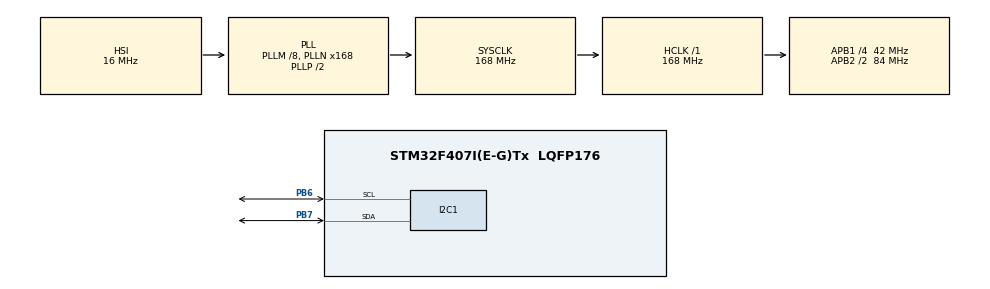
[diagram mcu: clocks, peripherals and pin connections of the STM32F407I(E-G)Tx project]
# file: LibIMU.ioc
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Mcu.Family=STM32F4
Mcu.Name=STM32F407I(E-G)Tx
Mcu.Package=LQFP176
NVIC.PriorityGroup=NVIC_PRIORITYGROUP_4
NVIC.TIM7_IRQn=true\:0\:0\:false\:false\:true\:true\:true\:true
PB6.Mode=I2C
PB6.Signal=I2C1_SCL
PB7.Mode=I2C
PB7.Signal=I2C1_SDA
ProjectManager.HeapSize=0x200
ProjectManager.StackSize=0x400
ProjectManager.TargetToolchain=STM32CubeIDE
RCC.48MHZClocksFreq_Value=84000000
RCC.AHBFreq_Value=168000000
RCC.APB1CLKDivider=RCC_HCLK_DIV4
RCC.APB1Freq_Value=42000000
RCC.APB1TimFreq_Value=84000000
RCC.APB2CLKDivider=RCC_HCLK_DIV2
RCC.APB2Freq_Value=84000000
RCC.APB2TimFreq_Value=168000000
RCC.CortexFreq_Value=168000000
RCC.HCLKFreq_Value=168000000
RCC.HSE_VALUE=25000000
RCC.HSI_VALUE=16000000
RCC.LSE_VALUE=32768
RCC.PLLM=8
RCC.PLLN=168
RCC.SYSCLKFreq_VALUE=168000000
RCC.SYSCLKSource=RCC_SYSCLKSOURCE_PLLCLK
RCC.VCOOutputFreq_Value=336000000
TIM7.Period=21000-1
TIM7.Prescaler=100-1
VP_TIM7_VS_ClockSourceINT.Mode=Enable_Timer
board=custom

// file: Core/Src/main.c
/* USER CODE BEGIN Header */
/**
  ******************************************************************************
  * @file           : main.c
  * @brief          : Main program body
  ******************************************************************************
  * @attention
  *
  * Copyright (c) 2022 STMicroelectronics.
  * All rights reserved.
  *
  * This software is licensed under terms that can be found in the LICENSE file
  * in the root directory of this software component.
  * If no LICENSE file comes with this software, it is provided AS-IS.
  *
  ******************************************************************************
  */
/* USER CODE END Header */
#include "main.h"

/* USER CODE BEGIN Includes */

#include "Inc/IMU.h"

/* USER CODE END Includes */

// I2C_HandleTypeDef hi2c1;

TIM_HandleTypeDef htim7;

/* USER CODE BEGIN PV */

 int Test=0;
/* USER CODE END PV */

void SystemClock_Config(void);
static void MX_GPIO_Init(void);
static void MX_I2C1_Init(void);
static void MX_TIM7_Init(void);

/* USER CODE BEGIN 0 */
 void HAL_TIM_PeriodElapsedCallback (TIM_HandleTypeDef *htim)
 {
 	if(htim==&htim7)
 	{

	UpdateRpy();

//
//
// 				/********** ACCEL data ***********/
// 		        // get the accelerometer data relative to the 3 axis :
// 				AccEst[0] =GetAccX() ;
// 				AccEst[1] = GetAccY() ;
// 				AccEst[2] = GetAccZ() ;
//
// 		        /********** MAG data ***********/
// 		         // get the magnetometer data relative to the 3 axis :
// 		        MagEst[0] = GetMagX() ;
// 		        MagEst[1] = GetMagY() ;
// 		        MagEst[2] = GetMagZ() ;
//
// 		        //KALMAN FILTERS:
// 		        //  application of the Kalman filter on the data of the three sensors
// 		        KalmanFilterACC(AccEst) ;
// 		        //  KalmanFilterGYRO(GYRO_est) ;
// 		        KalmanFilterMAG(MagEst) ;
//
//
// 		        // Normalize the data :
// 		         NormMag = sqrtf ((MagEst[0]*MagEst[0])+(MagEst[1]*MagEst[1])+(MagEst[2]*MagEst[2])) ;
// 		         MagEst[0] = MagEst[0]/NormMag ;
// 		         MagEst[1] = MagEst[1]/NormMag ;
// 		         MagEst[2] = MagEst[2]/NormMag ;
//
// 		         NormAcc = sqrt((AccEst[0]*AccEst[0])+(AccEst[1]*AccEst[1])+(AccEst[2]*AccEst[2])) ;
// 		         AccEst[0] = AccEst[0]/NormAcc ;
// 		         AccEst[1] = AccEst[1]/NormAcc ;
// 		         AccEst[2] = AccEst[2]/NormAcc ;
//
//
//
//
//
// 		        //Calculation of the three angles:
// 		          RollDeg =  180*atan2f(AccEst[1],AccEst[2])/M_PI;
// 		          PitchDeg = 180*atan2f(AccEst[0],AccEst[2])/M_PI;
// 		          Roll =  atan2f(AccEst[1],AccEst[2]);
// 		          Pitch = atan2f(AccEst[0],AccEst[2]);
// 		          Yaw=180*atan2f((-MagEst[1]*cosf(Roll)+MagEst[2]*sinf(Roll)),(MagEst[0]*cosf(Pitch)+MagEst[1]*sinf(Pitch)*sinf(Roll)+MagEst[2]*sinf(Pitch)*cos(Roll)))/M_PI+180;
// 		          if (Yaw>0) Yaw = Yaw-360 ;
// 		          Yaw=-Yaw;

 	}

 }
/* USER CODE END 0 */

int main(void)
{

  /* MCU Configuration--------------------------------------------------------*/

  /* Reset of all peripherals, Initializes the Flash interface and the Systick. */
  HAL_Init();

  /* Configure the system clock */
  SystemClock_Config();

  /* Initialize all configured peripherals */
  MX_GPIO_Init();
  MX_I2C1_Init();
  MX_TIM7_Init();
  /* USER CODE BEGIN 2 */
Test=  Setup();

SetAccBias(915.12,  492.0,  -1203.31) ;

SetGyroBias(-78.21, -437.85  , 398.19) ;

SetMagBias( 256.83, -143.9 , -246.92 ) ;

SetMagScale( 0.87,  1.38,  0.88) ;

HAL_TIM_Base_Start_IT(&htim7);

  /* USER CODE END 2 */

  /* Infinite loop */
  while (1)
  {

    /* USER CODE BEGIN 3 */
	 Update();

  }
  /* USER CODE END 3 */
}

void SystemClock_Config(void)
{
  RCC_OscInitTypeDef RCC_OscInitStruct = {0};
  RCC_ClkInitTypeDef RCC_ClkInitStruct = {0};

  /** Configure the main internal regulator output voltage
  */
  __HAL_RCC_PWR_CLK_ENABLE();
  __HAL_PWR_VOLTAGESCALING_CONFIG(PWR_REGULATOR_VOLTAGE_SCALE1);

  /** Initializes the RCC Oscillators according to the specified parameters
  * in the RCC_OscInitTypeDef structure.
  */
  RCC_OscInitStruct.OscillatorType = RCC_OSCILLATORTYPE_HSI;
  RCC_OscInitStruct.HSIState = RCC_HSI_ON;
  RCC_OscInitStruct.HSICalibrationValue = RCC_HSICALIBRATION_DEFAULT;
  RCC_OscInitStruct.PLL.PLLState = RCC_PLL_ON;
  RCC_OscInitStruct.PLL.PLLSource = RCC_PLLSOURCE_HSI;
  RCC_OscInitStruct.PLL.PLLM = 8;
  RCC_OscInitStruct.PLL.PLLN = 168;
  RCC_OscInitStruct.PLL.PLLP = RCC_PLLP_DIV2;
  RCC_OscInitStruct.PLL.PLLQ = 4;
  if (HAL_RCC_OscConfig(&RCC_OscInitStruct) != HAL_OK)
  {
    Error_Handler();
  }

  /** Initializes the CPU, AHB and APB buses clocks
  */
  RCC_ClkInitStruct.ClockType = RCC_CLOCKTYPE_HCLK|RCC_CLOCKTYPE_SYSCLK
                              |RCC_CLOCKTYPE_PCLK1|RCC_CLOCKTYPE_PCLK2;
  RCC_ClkInitStruct.SYSCLKSource = RCC_SYSCLKSOURCE_PLLCLK;
  RCC_ClkInitStruct.AHBCLKDivider = RCC_SYSCLK_DIV1;
  RCC_ClkInitStruct.APB1CLKDivider = RCC_HCLK_DIV4;
  RCC_ClkInitStruct.APB2CLKDivider = RCC_HCLK_DIV2;

  if (HAL_RCC_ClockConfig(&RCC_ClkInitStruct, FLASH_LATENCY_5) != HAL_OK)
  {
    Error_Handler();
  }
}

static void MX_I2C1_Init(void)
{

  hi2c1.Instance = I2C1;
  hi2c1.Init.ClockSpeed = 100000;
  hi2c1.Init.DutyCycle = I2C_DUTYCYCLE_2;
  hi2c1.Init.OwnAddress1 = 0;
  hi2c1.Init.AddressingMode = I2C_ADDRESSINGMODE_7BIT;
  hi2c1.Init.DualAddressMode = I2C_DUALADDRESS_DISABLE;
  hi2c1.Init.OwnAddress2 = 0;
  hi2c1.Init.GeneralCallMode = I2C_GENERALCALL_DISABLE;
  hi2c1.Init.NoStretchMode = I2C_NOSTRETCH_DISABLE;
  if (HAL_I2C_Init(&hi2c1) != HAL_OK)
  {
    Error_Handler();
  }

}

static void MX_TIM7_Init(void)
{

  TIM_MasterConfigTypeDef sMasterConfig = {0};

  htim7.Instance = TIM7;
  htim7.Init.Prescaler = 100-1;
  htim7.Init.CounterMode = TIM_COUNTERMODE_UP;
  htim7.Init.Period = 21000-1;
  htim7.Init.AutoReloadPreload = TIM_AUTORELOAD_PRELOAD_DISABLE;
  if (HAL_TIM_Base_Init(&htim7) != HAL_OK)
  {
    Error_Handler();
  }
  sMasterConfig.MasterOutputTrigger = TIM_TRGO_RESET;
  sMasterConfig.MasterSlaveMode = TIM_MASTERSLAVEMODE_DISABLE;
  if (HAL_TIMEx_MasterConfigSynchronization(&htim7, &sMasterConfig) != HAL_OK)
  {
    Error_Handler();
  }

}

static void MX_GPIO_Init(void)
{

  /* GPIO Ports Clock Enable */
  __HAL_RCC_GPIOB_CLK_ENABLE();

}

void Error_Handler(void)
{
  __disable_irq();
  while (1)
  {
  }
}
